# YTM32B1HA0 register map
Vendor: YTMicro; File version: 1.0
CPU: little endian, MPU, FPU, 2 interrupt priority bits
Registers are 32-bit, read-write, reset 0x0 unless marked. A register's access mark holds for its fields unless they carry their own. Offsets are from the block's base; [hi:lo] are bit positions; {n}, {i} and the like mark numbered series; 'fields as' and 'values as' point back to an identical list.

## SCU — System Clock Unit of Microcontroller
Base 0x401F0000; register names take the prefix SCU_
0x00 CLKS — The register contains system clock source selection bit, the system clock source is the root of system clock divider which generates Core/Platform Clock, Fast Bus Clock and Slow Bus Clock.
  [1:0] CLKSRCSEL — Select System Clock Source.
    0=Select FIRC as system clock source; 1=Select PLL as system clock source; 2=Select FXOSC as system clock source; 3=Select SIRC as system clock source
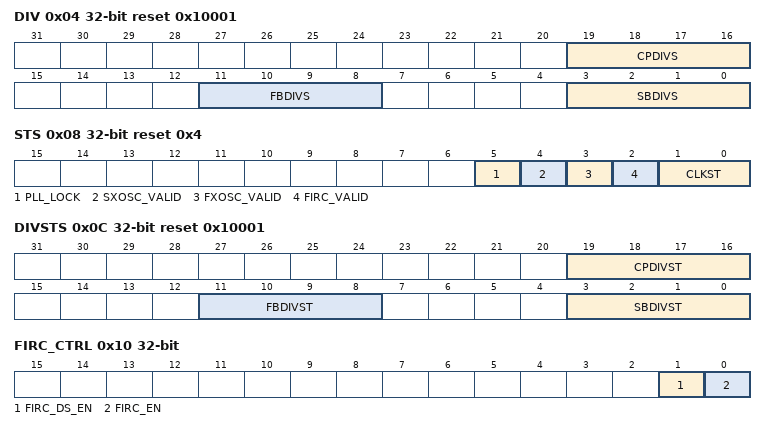
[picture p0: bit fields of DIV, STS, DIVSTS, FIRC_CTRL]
0x04 DIV reset 0x10001 — This register controls the system clock divider which generates Core Platform Clock, Fast Bus Clock and Slow Bus Clock.
  [all] fields
    {v}=Divide by {v+1} (v=0..15)
  [19:16] CPDIVS
  [11:8] FBDIVS
  [3:0] SBDIVS
0x08 STS ro reset 0x4 — System Clock Unit Status register
  [5] PLL_LOCK
    0=PLL unlocked; 1=PLL locked
  [4] SXOSC_VALID
    0=SXOSC Clock invalid; 1=SXOSC Clock valid
  [3] FXOSC_VALID
    0=FXOSC Clock invalid; 1=FXOSC Clock valid
  [2] FIRC_VALID
    0=FIRC Clock invalid; 1=FIRC Clock valid
  [1:0] CLKST
    0=FIRC is selected as system clock source; 1=PLL is selected as system clock source; 2=FXOSC is selected as system clock source; 3=SIRC is selected as system clock source
0x0C DIVSTS ro reset 0x10001 — System Clock Unit clock divider status, check this register after any change of divider value.
  [all] fields
    {v}=Divide by {v+1} (v=0..15)
  [19:16] CPDIVST
  [11:8] FBDIVST
  [3:0] SBDIVST
0x10 FIRC_CTRL — FIRC control register
  [1] FIRC_DS_EN — Enable/Disable FIRC when chip enters Deepsleep mode.
    0=Disable FIRC when chip enters Deepsleep mode; 1=Enable FIRC when chip enters Deepsleep mode
  [0] FIRC_EN — Enable/Disable FIRC regardless it is selected as system clock source..
    0=Disable FIRC if it is not selected as system clock source; 1=Enable FIRC regardless it is selected as system clock or not
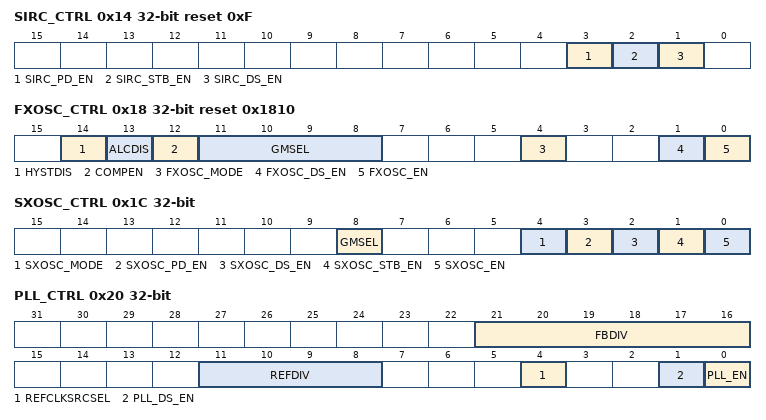
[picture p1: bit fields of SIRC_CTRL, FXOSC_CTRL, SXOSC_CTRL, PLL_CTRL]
0x14 SIRC_CTRL reset 0xF — SIRC control register
  [3] SIRC_PD_EN — Enable/Disable SIRC when chip enters Powerdown mode.
    0=Disable SIRC when chip enters Powerdown mode; 1=Enable SIRC when chip enters Powerdown mode
  [2] SIRC_STB_EN — Enable/Disable SIRC when chip enters Standby mode.
    0=Disable SIRC when chip enters Standby mode; 1=Enable SIRC when chip enters Standby mode
  [1] SIRC_DS_EN — Enable/Disable SIRC when chip enters Deepsleep mode.
    0=Disable SIRC when chip enters Deepsleep mode; 1=Enable SIRC when chip enters Deepsleep mode
0x18 FXOSC_CTRL reset 0x1810 — FXOSC control register
  [14] HYSTDIS — This bit should not be changed when FXOSC_VALID is high
  [13] ALCDIS — This bit should not be changed when FXOSC_VALID is high
  [12] COMPEN — Comp enable bit, this bit should be high when crystal mode is used, and it should be low when bypass mode is used, and it should not be changed when FXOSC_VALID is high
  [11:8] GMSEL — Gain select bit, higher gain value results higher power and better performance, it only impact FXOSC crystal mode, and it should not be changed when FXOSC_VALID is high
  [4] FXOSC_MODE — Select FXOSC crystal mode or bypass mode, it should not be changed when FXOSC_VALID is high
    0=FXOSC bypass mode; 1=FXOSC crystal mode
  [1] FXOSC_DS_EN — Enable/Disable FXOSC when chip enters Deepsleep mode.
    0=Disable FXOSC when chip enters Deepsleep mode; 1=Enable FXOSC when chip enters Deepsleep mode
  [0] FXOSC_EN — Enable/Disable Fast Crystal Oscillator(FXOSC) regardless it is selected as system clock source..
    0=Disable FXOSC if it is not selected as system clock source; 1=Enable FXOSC regardless it is selected as system clock or not
0x1C SXOSC_CTRL — SXOSC control register
  [8] GMSEL — SXOSC Gain select bit
  [4] SXOSC_MODE — Select SXOSC oscillator mode or bypass mode
    0=SXOSC bypass mode; 1=SXOSC crystal mode
  [3] SXOSC_PD_EN — Enable/Disable SXOSC when chip enters Powerdown mode.
    0=Disable SXOSC when chip enters Standby mode; 1=Enable SXOSC when chip enters Standby mode
  [2] SXOSC_DS_EN — Enable/Disable SXOSC when chip enters Deepsleep mode.
    0=Disable SXOSC when chip enters Deepsleep mode; 1=Enable SXOSC when chip enters Deepsleep mode
  [1] SXOSC_STB_EN — Enable/Disable SXOSC when chip enters Standby mode.
    values as SXOSC_PD_EN
  [0] SXOSC_EN — Enable/Disable SXOSC
    0=Disable SXOSC; 1=Enable SXOSC
0x20 PLL_CTRL — System Clock Unit PLL control register, changes to this register should be done when PLL is disabled to prevent glitches to system clock source.
  [21:16] FBDIV — The FBDIV bits establish the value of the divider in th PLL feedabck loop. Please refer to \hyperref[phase-locked-loop-clockpll]{Phase-Locked Loop Clock(PLL)}.
  [11:8] REFDIV — Selects the amount to divide down the reference clock for the PLL. Please refer to \hyperref[phase-locked-loop-clockpll]{Phase-Locked Loop Clock(PLL)}.
  [4] REFCLKSRCSEL — PLL reference clock source select bit
    0=Select FXOSC as PLL reference clock; 1=Select FIRC as PLL reference clock
  [1] PLL_DS_EN — Enable/Disable PLL when chip enters Deepsleep mode.
    0=Disable PLL when chip enters Deepsleep mode; 1=Enable PLL when chip enters Deepsleep mode
  [0] PLL_EN — Enable/Disable PLL regardless it is selected as system clock source.
    0=Disable PLL if it is not selected as system clock source; 1=Enable PLL regardless it is selected as system clock or not
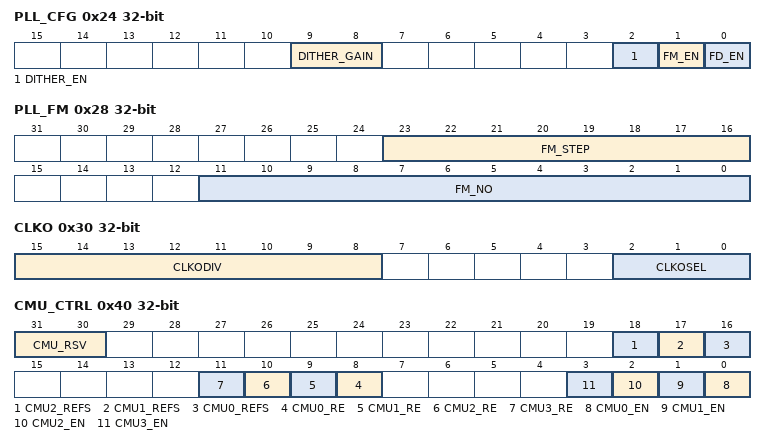
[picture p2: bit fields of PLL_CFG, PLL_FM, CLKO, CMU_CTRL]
0x24 PLL_CFG
  [9:8] DITHER_GAIN — Dither gain control bit. Replace one bit of the accumulator output SUM_SUB[3:0] with the output D0 of the LFSR.
    {v}=SUM_SUB[{v}] is replaced by D0 (v=0..3)
  [2] DITHER_EN — Enable/Disable dither
    0=Disabled; 1=Enabled
  [1] FM_EN — Enable/Disable spread spectrum mode.
    0=Disabled; 1=Enabled
  [0] FD_EN — Enable/Disable Fractional mode.
    0=Disabled; 1=Enabled
0x28 PLL_FM
  [23:16] FM_STEP — In Frequency Modulation mode, FM_STEP provides the step size for modulation depth and frequency.
  [11:0] FM_NO — In Frequency Modulation mode, FM_NO provides the number of steps to achieve modulation depth.
0x2C PLL_FD
  [14:0] FD_FRAC — The value of this field must be less than 32768. In integer mode, it must be set to 0.
0x30 CLKO — This register is to select the clock sources to output to chip IOs for external use.
  [15:8] CLKODIV — \begin{itemize}[label={}, leftmargin=*] \itemsep1pt\parskip0pt\parsep0pt \item 00000000b - DIV disable \item 00000001b - DIV disable \item xxxxxx1xb - DIV as the divider value \vspace*{-\baselineskip} \end{itemize}
  [2:0] CLKOSEL
    0=None clock select to output; 1=FIRC clock output; 2=SIRC clock output; 3=FXOSC clock output; 4=SXOSC clock output; 5=PLL clock output; 6=TRNG ring oscillator otuput; 7=Core clock output
0x40 CMU_CTRL — System Clock Unit Clock Monitor Unit control register
  [31:30] CMU_RSV — The register bits are reseted by global reset.
  [18] CMU2_REFS — Select reference clock of CMU2
    0=SIRC selected as reference clock of CMU; 1=FXOSC selected as reference clock of CMU
  [17] CMU1_REFS — Select reference clock of CMU1
    values as CMU2_REFS
  [16] CMU0_REFS — Select reference clock of CMU0
    values as CMU2_REFS
  [n+8] CMU{n}_RE (n=0..3) — Enable/Disable reset when CMU{n} event happens
    0=Reset disable when CMU event happens; 1=Reset enable when CMU event happens
  [n] CMU{n}_EN (n=0..3) — Enable/Disable CMU{n}
    0=CMU disable; 1=CMU enable
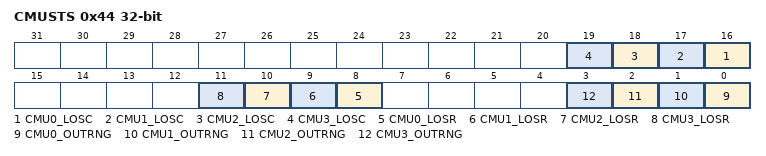
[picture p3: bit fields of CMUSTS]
0x44 CMUSTS — System Clock Unit Clock Monitor Unit status register
  [n+16] CMU{n}_LOSC (n=0..3) — Indicates CMU{n} loss of clock event
    0=Checked Clock of CMU{n} is available; 1=Checked Clock of CMU{n} is lost
  [n+8] CMU{n}_LOSR (n=0..3) — Indicates CMU{n} loss of reference clock event
    0=Reference Clock of CMU{n} is available; 1=Reference Clock of CMU{n} is lost
  [n] CMU{n}_OUTRNG (n=0..3) — Indicates Checked Clock of CMU{n} is out of range
    0=Checked Clock of CMU{n} is out of range; 1=Reference Clock of CMU{n} is lost
{0x48+8i} CMUCMP{i}_HIGH reset 0xFFFF (i=0..3) — System Clock Unit Clock Monitor High Comparison Value Register
  [15:0] VAL
{0x4C+8i} CMUCMP{i}_LOW (i=0..3) — System Clock Unit Clock Monitor Low Comparison Value Register
  [15:0] VAL
